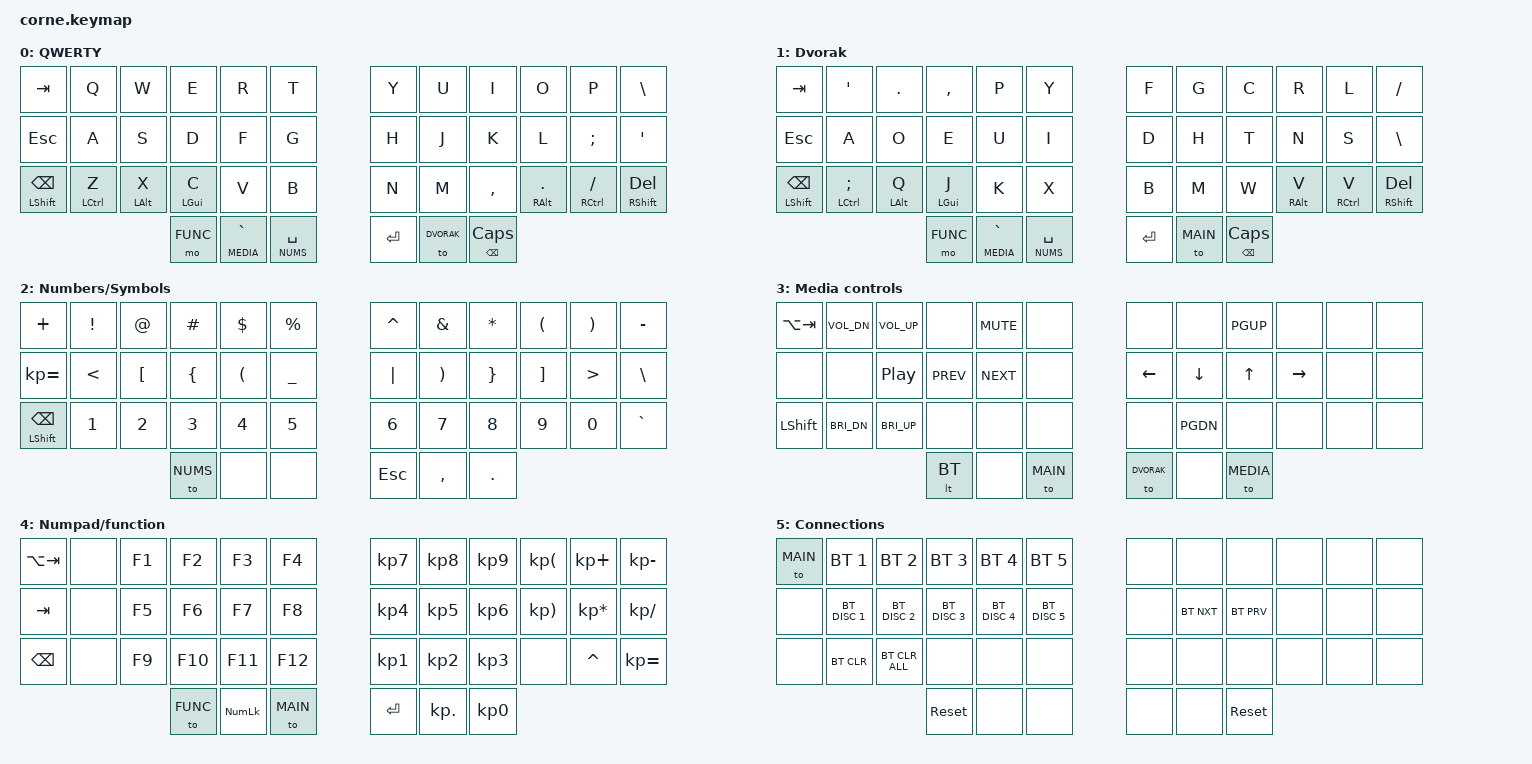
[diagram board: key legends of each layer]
#include <behaviors.dtsi>
#include <dt-bindings/zmk/keys.h>
#include <dt-bindings/zmk/bt.h>

#define MAIN   0
#define DVORAK 1
#define NUMS   2
#define MEDIA  3
#define FUNC   4
#define BT     5

&mt {
    flavor = "balanced";
};

/ {
    keymap {
        compatible = "zmk,keymap";

        default_layer {
            display-name = "QWERTY";
// -----------------------------------------------------------------------------------------
// |    TAB    |    Q    |   W    |    E     |    R    |    T   ||   Y   |   U    |  I   |   O    |    P    |    \     |
// |    ESC    |    A    |   S    |    D     |    F    |    G   ||   H   |   J    |  K   |   L    |    ;    |    '     |
// | SHFT,BSPC | Z,LCTRL | X,LALT |  C,LGUI  |    V    |    B   ||   N   |   M    |  ,   | .,RALT | /,RCTRL | SHFT,DLT |
//                                | Num/func | `,Media | ⎵,Nums || ENTER | Dvorak | CAPS |
// -----------------------------------------------------------------------------------------
            bindings = <
    &kp TAB         &kp Q       &kp W       &kp E       &kp R               &kp T           &kp Y   &kp U       &kp I       &kp O           &kp P           &kp BSLH
    &kp ESC         &kp A       &kp S       &kp D       &kp F               &kp G           &kp H   &kp J       &kp K       &kp L           &kp SEMI        &kp SQT
    &mt LSHFT BSPC  &mt LCTRL Z &mt LALT X  &mt LGUI C  &kp V               &kp B           &kp N   &kp M       &kp COMMA   &mt RALT DOT    &mt RCTRL FSLH  &mt RSHFT DELETE
                                            &mo FUNC    &lt MEDIA GRAVE     &lt NUMS SPACE  &kp RET &to DVORAK  &mt BSPC CAPS
                >;
            };
        
        dvorak_layer {
            display-name = "Dvorak";
// -----------------------------------------------------------------------------------------
// |    TAB    |    "    |   ,    |    .     |    P    |   Y    ||   F   |   G    |  C   |   R    |    L    |    /     |
// |    ESC    |    A    |   O    |    E     |    U    |   I    ||   D   |   H    |  T   |   N    |    S    |    \     |
// | SHFT,BSPC | ;,LCTRL | Q,LALT |  J,LGUI  |    K    |   X    ||   B   |   M    |  W   | V,RALT | Z,RCTRL | SHFT,DLT |
//                                | Num/func | `,Media | ⎵,Nums || ENTER | QWERTY | CAPS |
// -----------------------------------------------------------------------------------------
            bindings = <
    &kp TAB         &kp SQT         &kp DOT     &kp COMMA   &kp P               &kp Y           &kp F   &kp G       &kp C       &kp R      &kp L           &kp FSLH
    &kp ESC         &kp A           &kp O       &kp E       &kp U               &kp I           &kp D   &kp H       &kp T       &kp N      &kp S           &kp BSLH
    &mt LSHFT BSPC  &mt LCTRL SEMI  &mt LALT Q  &mt LGUI J  &kp K               &kp X           &kp B   &kp M       &kp W       &mt RALT V &mt RCTRL V     &mt RSHFT DELETE
                                                &mo FUNC    &lt MEDIA GRAVE     &lt NUMS SPACE  &kp RET &to MAIN    &mt BSPC CAPS
                >;
            };

        symbols_layer {
            display-name = "Numbers/Symbols";
// -----------------------------------------------------------------------------------------
// |   +   |  !  |  @  |    #    |  $  |  %  ||  ^  |  &  |  *  |  (  |  )  |  -  |
// |   =   |  <  |  [  |    {    |  (  |  _  ||  |  |  )  |  }  |  ]  |  >  |  \  |
// | Sh/Bs |  1  |  2  |    3    |  4  |  5  ||  6  |  7  |  8  |  9  |  0  |  `  |
//                     | SymLock |     |     || ESC |  ,  |  .  | 
// -----------------------------------------------------------------------------------------
                bindings = <
    &kp PLUS        &kp EXCL    &kp AT      &kp HASH        &kp DOLLAR  &kp PRCNT   &kp CARET   &kp AMPS    &kp STAR    &kp LPAR    &kp RPAR    &kp MINUS
    &kp KP_EQUAL    &kp LT      &kp LBKT    &kp LBRC        &kp LPAR    &kp UNDER   &kp PIPE    &kp RPAR    &kp RBRC    &kp RBKT    &kp GT      &kp BSLH
    &mt LSHFT BSPC  &kp N1      &kp N2      &kp N3          &kp N4      &kp N5      &kp N6      &kp N7      &kp N8      &kp N9      &kp N0      &kp GRAVE
                                            &to NUMS        &none       &none       &kp ESC     &kp COMMA   &kp DOT
                >;
            };

        media_layer {
            display-name = "Media controls";
// -----------------------------------------------------------------------------------------
// | AltTab | Volume- | Volume+ |      | Mute |      ||        |      |  PgUp   |       |   |   |
// |        |         |  Pause  | Prev | Next |      ||  Left  | Down |   Up    | Right |   |   |
// |  Shft  | Bright- | Bright+ |      |      |      ||        | PgDn |         |       |   |   |
//                              |  BT  |      | MAIN || Dvorak |      | MedLock |
// -----------------------------------------------------------------------------------------
            bindings = <
    &kp LA(TAB) &kp C_VOL_DN    &kp C_VOL_UP    &none       &kp C_MUTE  &none       &none       &none       &kp PGUP    &none       &none   &none   
    &none       &none           &kp C_PP        &kp C_PREV  &kp C_NEXT  &none       &kp LEFT    &kp DOWN    &kp UP      &kp RIGHT   &none   &none
    &kp LSHFT   &kp C_BRI_DN    &kp C_BRI_UP    &none       &none       &none       &none       &kp PGDN    &none       &none       &none   &none
                                                &lt BT      &none       &to MAIN    &to DVORAK  &none       &to MEDIA
                >;
            };
        
        numpad_layer {
            display-name = "Numpad/function";
// -----------------------------------------------------------------------------------------
// | AltTab |   | F01 |  F02   |   F03   | F04  ||   7   | 8 | 9 | ( | + | - |
// |  Tab   |   | F05 |  F06   |   F07   | F08  ||   4   | 5 | 6 | ) | * | / |
// |  BSpc  |   | F09 |  F10   |   F11   | F12  ||   1   | 2 | 3 |   | ^ | = |
//                    | FnLock | NumLock | MAIN || ENTER | . | 0 |
// -----------------------------------------------------------------------------------------
            bindings = <
    &kp LA(TAB) &none   &kp F1  &kp F2  &kp F3      &kp F4      &kp KP_N7   &kp KP_N8   &kp KP_N9   &kp KP_LPAR &kp KP_PLUS     &kp KP_MINUS
    &kp TAB     &none   &kp F5  &kp F6  &kp F7      &kp F8      &kp KP_N4   &kp KP_N5   &kp KP_N6   &kp KP_RPAR &kp KP_MULTIPLY &kp KP_SLASH
    &kp BSPC    &none   &kp F9  &kp F10 &kp F11     &kp F12     &kp KP_N1   &kp KP_N2   &kp KP_N3   &none       &kp CARET       &kp KP_EQUAL
                                        &to FUNC    &kp KP_NLCK &to MAIN    &kp ENTER   &kp KP_DOT  &kp KP_N0
                >;
            };
        
        bluetooth_layer {
            display-name = "Connections";
// This layer has keys 
// -----------------------------------------------------------------------------------------
// | MAIN |  Device 1  |  Device 2  |  Device 3  | Device 4 | Device 5 ||   |              |              |   |   |   |
// |      | Disconn. 1 | Disconn. 2 |  Disc. 3   | Disc. 4  | Disc. 5  ||   | Next profile | Prev profile |   |   |   |
// |      | Clear this | Clear all  |            |          |          ||   |              |              |   |   |   |
//                                  | Reset half |          |          ||   |              |  Reset half  |
// -----------------------------------------------------------------------------------------
            bindings = <
    &to MAIN    &bt BT_SEL 1    &bt BT_SEL 2    &bt BT_SEL 3    &bt BT_SEL 4    &bt BT_SEL 5    &none   &none       &none       &none   &none   &none 
    &none       &bt BT_DISC 1   &bt BT_DISC 2   &bt BT_DISC 3   &bt BT_DISC 4   &bt BT_DISC 5   &none   &bt BT_NXT  &bt BT_PRV  &none   &none   &none
    &none       &bt BT_CLR      &bt BT_CLR_ALL  &none           &none           &none           &none   &none       &none       &none   &none   &none
                                                &sys_reset      &none           &none           &none   &none       &sys_reset
                >;
            };

        };
};
